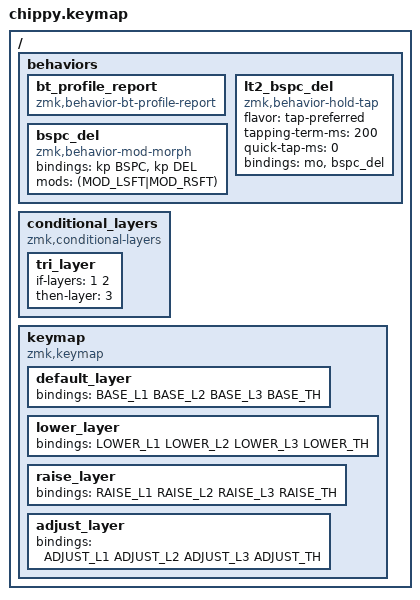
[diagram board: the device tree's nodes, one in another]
#include <behaviors.dtsi>
#include <dt-bindings/zmk/keys.h>
#include <dt-bindings/zmk/bt.h>
#include <dt-bindings/zmk/modifiers.h>

/* =========================================================
 * Key aliases
 * ========================================================= */

#define TMUX LC(A)


/* =========================================================
 * Default layer (QWERTY)
 * ========================================================= */

#define BASE_L1 \
  &kp LGUI   &kp Q      &kp W      &kp E      &kp R      &kp T            &kp Y      &kp U      &kp I      &kp O      &kp P      &kp INS

#define BASE_L2 \
  &sk LCTRL  &kp A      &kp S      &kp D      &kp F      &kp G            &kp H      &kp J      &kp K      &kp L      &kp SEMI   &kp SQT

#define BASE_L3 \
  &sk LSHIFT &kp Z      &kp X      &kp C      &kp V      &kp B           &kp N      &kp M      &kp COMMA  &kp DOT    &kp FSLH   &kp DEL

#define BASE_TH \
      &mt LSHFT TMUX  &lt 1 TAB        &mt LCTRL SPACE \
      &mt LALT RET    &lt2_bspc_del 2 0       &kp ESC


/* =========================================================
 * Lower layer
 * ========================================================= */

#define LOWER_L1 \
  &kp LGUI   &kp HOME          &kp EXCL   &kp AT      &kp HASH   &kp PG_UP      &kp MINUS   &kp EQUAL   &trans     &trans     &trans     &trans

#define LOWER_L2 \
  &trans     &kp END           &kp DLLR   &kp PRCNT   &kp CARET  &kp RPAR       &kp LEFT    &kp DOWN    &kp UP     &kp RIGHT   &kp GRAVE   &trans

#define LOWER_L3 \
  &trans     &kp DEL           &kp AMPS   &kp ASTRK   &kp LPAR   &kp PG_DN      &trans      &trans      &trans     &trans     &trans     &trans

#define LOWER_TH \
      &trans  &trans  &trans \
      &trans  &trans  &bt_profile_report


/* =========================================================
 * Raise layer
 * ========================================================= */

#define RAISE_L1 \
  &trans     &trans   &kp N1   &kp N2   &kp N3   &trans      &kp BSLH &kp LBRC &kp RBRC &kp EQUAL &kp MINUS &kp GRAVE

#define RAISE_L2 \
  &trans     &trans   &kp N4   &kp N5   &kp N6   &kp N0       &kp PIPE &kp LPAR &kp RPAR &kp PLUS  &kp UNDER &kp TILDE

#define RAISE_L3 \
  &trans     &trans   &kp N7   &kp N8   &kp N9   &trans       &kp FSLH &kp LBKT &kp RBKT &kp CARET &kp AMPS &kp ASTRK

#define RAISE_TH \
      &trans  &trans  &trans \
      &trans  &trans  &trans


/* =========================================================
 * Adjust layer
 * ========================================================= */

#define ADJUST_L1 \
  &kp AT      &trans        &trans        &trans        &trans        &trans        &trans   &trans   &trans   &trans   &trans   &trans

#define ADJUST_L2 \
  &bt BT_CLR  &bt BT_SEL 0  &bt BT_SEL 1  &bt BT_SEL 2  &bt BT_SEL 3  &bt BT_SEL 4  &trans   &trans   &trans   &trans   &trans   &trans

#define ADJUST_L3 \
  &bootloader &trans        &trans        &trans        &trans        &trans        &trans   &trans   &trans   &trans   &trans   &bootloader

#define ADJUST_TH \
      &trans  &trans  &trans \
      &trans  &trans  &trans



/ {

    behaviors {
        bt_profile_report: bt_profile_report {
            compatible = "zmk,behavior-bt-profile-report";
            #binding-cells = <0>;
        };

        bspc_del: bspc_del {
            compatible = "zmk,behavior-mod-morph";
            #binding-cells = <0>;
            bindings = <&kp BSPC>, <&kp DEL>;
            mods = <(MOD_LSFT|MOD_RSFT)>;
        };

        lt2_bspc_del: lt2_bspc_del {
            compatible = "zmk,behavior-hold-tap";
            #binding-cells = <2>;
            flavor = "tap-preferred";
            tapping-term-ms = <200>;
            quick-tap-ms = <0>;
            bindings = <&mo>, <&bspc_del>;
        };
    };

    conditional_layers {
        compatible = "zmk,conditional-layers";

        tri_layer {
            if-layers = <1 2>;
            then-layer = <3>;
        };
    };

    keymap {
        compatible = "zmk,keymap";

        default_layer {
            bindings = <
                BASE_L1
                BASE_L2
                BASE_L3
                       BASE_TH
            >;
        };

        lower_layer {
            bindings = <
                LOWER_L1
                LOWER_L2
                LOWER_L3
                       LOWER_TH
            >;
        };

        raise_layer {
            bindings = <
                RAISE_L1
                RAISE_L2
                RAISE_L3
                       RAISE_TH
            >;
        };

        adjust_layer {
            bindings = <
                ADJUST_L1
                ADJUST_L2
                ADJUST_L3
                        ADJUST_TH
            >;
        };

    };
};
